VERSION ""

NS_ :

BS_:

BU_: GENERIC_SENSOR_HUB

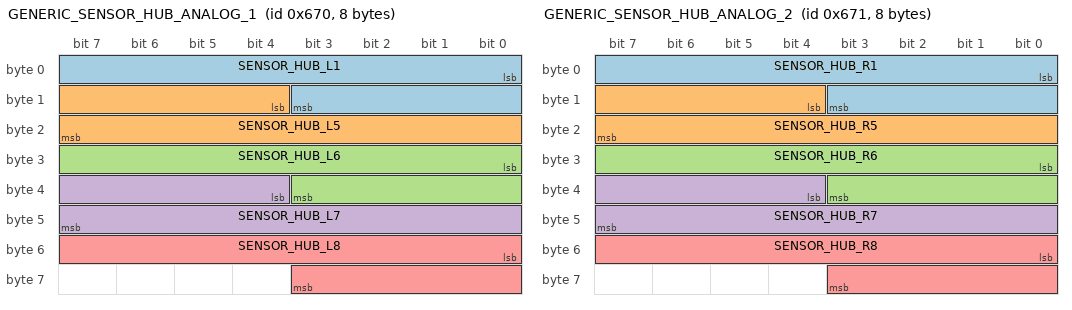
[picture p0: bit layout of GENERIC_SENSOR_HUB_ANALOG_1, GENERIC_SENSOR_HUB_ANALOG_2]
BO_ 1648 GENERIC_SENSOR_HUB_ANALOG_1: 8 GENERIC_SENSOR_HUB
 SG_ SENSOR_HUB_L1 : 0|12@1+ (0.0008058608058608059,0) [0|3.3] "V" Vector__XXX
 SG_ SENSOR_HUB_L5 : 12|12@1+ (0.0008058608058608059,0) [0|3.3] "V" Vector__XXX
 SG_ SENSOR_HUB_L6 : 24|12@1+ (0.0008058608058608059,0) [0|3.3] "V" Vector__XXX
 SG_ SENSOR_HUB_L7 : 36|12@1+ (0.0008058608058608059,0) [0|3.3] "V" Vector__XXX
 SG_ SENSOR_HUB_L8 : 48|12@1+ (0.0008058608058608059,0) [0|3.3] "V" Vector__XXX

BO_ 1649 GENERIC_SENSOR_HUB_ANALOG_2: 8 GENERIC_SENSOR_HUB
 SG_ SENSOR_HUB_R1 : 0|12@1+ (0.0008058608058608059,0) [0|3.3] "V" Vector__XXX
 SG_ SENSOR_HUB_R5 : 12|12@1+ (0.0008058608058608059,0) [0|3.3] "V" Vector__XXX
 SG_ SENSOR_HUB_R6 : 24|12@1+ (0.0008058608058608059,0) [0|3.3] "V" Vector__XXX
 SG_ SENSOR_HUB_R7 : 36|12@1+ (0.0008058608058608059,0) [0|3.3] "V" Vector__XXX
 SG_ SENSOR_HUB_R8 : 48|12@1+ (0.0008058608058608059,0) [0|3.3] "V" Vector__XXX

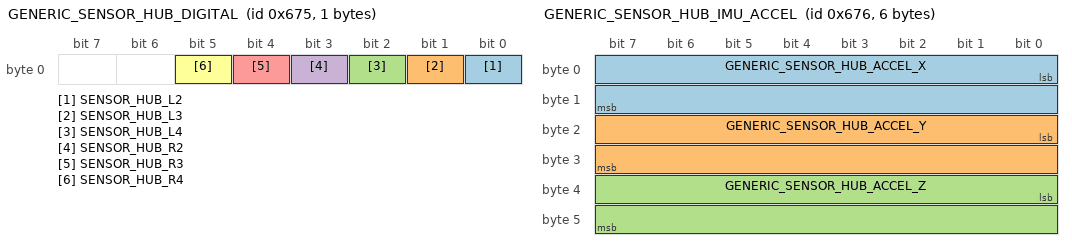
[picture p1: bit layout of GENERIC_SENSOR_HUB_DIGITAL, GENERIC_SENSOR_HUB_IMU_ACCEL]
BO_ 1653 GENERIC_SENSOR_HUB_DIGITAL: 1 GENERIC_SENSOR_HUB
 SG_ SENSOR_HUB_L2 : 0|1@1+ (1,0) [0|1] "bool" Vector__XXX
 SG_ SENSOR_HUB_L3 : 1|1@1+ (1,0) [0|1] "bool" Vector__XXX
 SG_ SENSOR_HUB_L4 : 2|1@1+ (1,0) [0|1] "bool" Vector__XXX
 SG_ SENSOR_HUB_R2 : 3|1@1+ (1,0) [0|1] "bool" Vector__XXX
 SG_ SENSOR_HUB_R3 : 4|1@1+ (1,0) [0|1] "bool" Vector__XXX
 SG_ SENSOR_HUB_R4 : 5|1@1+ (1,0) [0|1] "bool" Vector__XXX

BO_ 1654 GENERIC_SENSOR_HUB_IMU_ACCEL: 6 GENERIC_SENSOR_HUB
 SG_ GENERIC_SENSOR_HUB_ACCEL_X : 0|16@1- (0.000122,0) [-4|4] "g" Vector__XXX
 SG_ GENERIC_SENSOR_HUB_ACCEL_Y : 16|16@1- (0.000122,0) [-4|4] "g" Vector__XXX
 SG_ GENERIC_SENSOR_HUB_ACCEL_Z : 32|16@1- (0.000122,0) [-4|4] "g" Vector__XXX

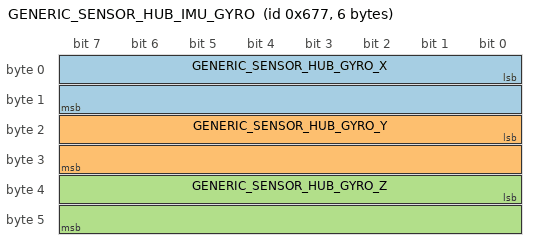
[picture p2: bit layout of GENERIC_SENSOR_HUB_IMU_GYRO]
BO_ 1655 GENERIC_SENSOR_HUB_IMU_GYRO: 6 GENERIC_SENSOR_HUB
 SG_ GENERIC_SENSOR_HUB_GYRO_X : 0|16@1- (0.0175,0) [-500|500] "dps" Vector__XXX
 SG_ GENERIC_SENSOR_HUB_GYRO_Y : 16|16@1- (0.0175,0) [-500|500] "dps" Vector__XXX
 SG_ GENERIC_SENSOR_HUB_GYRO_Z : 32|16@1- (0.0175,0) [-500|500] "dps" Vector__XXX

BO_ 1656 GENERIC_SENSOR_HUB_TEMP: 4 GENERIC_SENSOR_HUB
 SG_ GENERIC_SENSOR_HUB_IMU_TEMP : 0|16@1- (0.00390625,25) [-40|85] "degC" Vector__XXX
 SG_ GENERIC_SENSOR_HUB_AMBIENT_TEMP : 16|16@1- (0.0625,0) [-55|125] "degC" Vector__XXX

BO_ 1657 GENERIC_SENSOR_HUB_STATUS: 1 GENERIC_SENSOR_HUB
 SG_ GENERIC_SENSOR_HUB_ISM330_OK : 0|1@1+ (1,0) [0|1] "" Vector__XXX
 SG_ GENERIC_SENSOR_HUB_MCP9800_OK : 1|1@1+ (1,0) [0|1] "" Vector__XXX
